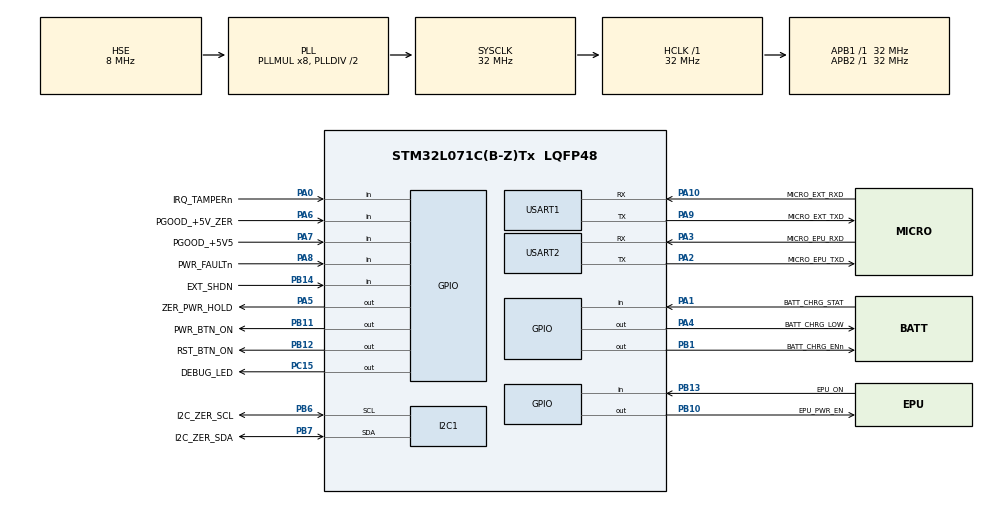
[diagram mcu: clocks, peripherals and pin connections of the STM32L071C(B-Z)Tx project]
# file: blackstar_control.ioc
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CRC.CRCLength=CRC_POLYLENGTH_16B
CRC.DefaultInitValueUse=DEFAULT_INIT_VALUE_DISABLE
CRC.DefaultPolynomialUse=DEFAULT_POLYNOMIAL_DISABLE
CRC.GeneratingPolynomial=X12+X5+X0
CRC.InitValue=0xFFFF
Dma.Request0=USART2_TX
Dma.Request1=USART2_RX
Dma.Request2=USART1_TX
Dma.Request3=USART1_RX
Dma.USART1_RX.3.Direction=DMA_PERIPH_TO_MEMORY
Dma.USART1_RX.3.Instance=DMA1_Channel3
Dma.USART1_RX.3.MemDataAlignment=DMA_MDATAALIGN_BYTE
Dma.USART1_RX.3.MemInc=DMA_MINC_ENABLE
Dma.USART1_RX.3.Mode=DMA_CIRCULAR
Dma.USART1_RX.3.PeriphDataAlignment=DMA_PDATAALIGN_BYTE
Dma.USART1_RX.3.PeriphInc=DMA_PINC_DISABLE
Dma.USART1_RX.3.Priority=DMA_PRIORITY_HIGH
Dma.USART1_TX.2.Direction=DMA_MEMORY_TO_PERIPH
Dma.USART1_TX.2.Instance=DMA1_Channel2
Dma.USART1_TX.2.MemDataAlignment=DMA_MDATAALIGN_BYTE
Dma.USART1_TX.2.MemInc=DMA_MINC_ENABLE
Dma.USART1_TX.2.Mode=DMA_NORMAL
Dma.USART1_TX.2.PeriphDataAlignment=DMA_PDATAALIGN_BYTE
Dma.USART1_TX.2.PeriphInc=DMA_PINC_DISABLE
Dma.USART1_TX.2.Priority=DMA_PRIORITY_LOW
Dma.USART2_RX.1.Direction=DMA_PERIPH_TO_MEMORY
Dma.USART2_RX.1.Instance=DMA1_Channel5
Dma.USART2_RX.1.MemDataAlignment=DMA_MDATAALIGN_BYTE
Dma.USART2_RX.1.MemInc=DMA_MINC_ENABLE
Dma.USART2_RX.1.Mode=DMA_CIRCULAR
Dma.USART2_RX.1.PeriphDataAlignment=DMA_PDATAALIGN_BYTE
Dma.USART2_RX.1.PeriphInc=DMA_PINC_DISABLE
Dma.USART2_RX.1.Priority=DMA_PRIORITY_HIGH
Dma.USART2_TX.0.Direction=DMA_MEMORY_TO_PERIPH
Dma.USART2_TX.0.Instance=DMA1_Channel4
Dma.USART2_TX.0.MemDataAlignment=DMA_MDATAALIGN_BYTE
Dma.USART2_TX.0.MemInc=DMA_MINC_ENABLE
Dma.USART2_TX.0.Mode=DMA_NORMAL
Dma.USART2_TX.0.PeriphDataAlignment=DMA_PDATAALIGN_BYTE
Dma.USART2_TX.0.PeriphInc=DMA_PINC_DISABLE
Dma.USART2_TX.0.Priority=DMA_PRIORITY_LOW
FREERTOS.BinarySemaphores01=uartTxSemaphore,Static,uartTxSemaphoreControlBlock
FREERTOS.Events01=uartEvents,Static,uartEventsControlBlock
FREERTOS.Queues01=epuTxQueue,2,TxQueueMsg_t,0,Static,epuTxQueueBuffer,epuTxQueueControlBlock;epuRxQueue,8,RxQueueMsg_t,0,Static,epuRxQueueBuffer,epuRxQueueControlBlock;extTxQueue,2,TxQueueMsg_t,0,Static,extTxQueueBuffer,extTxQueueControlBlock;extRxQueue,8,RxQueueMsg_t,0,Static,extRxQueueBuffer,extRxQueueControlBlock
FREERTOS.RecursiveMutexes01=crcMutex,Static,crcMutexControlBlock;i2cMutex,Static,i2cMutexControlBlock
FREERTOS.Tasks01=controllerTask,24,256,startControllerTask,Default,NULL,Static,controllerTaskBuffer,controllerTaskControlBlock;messageTask,24,1024,startMessageTask,Default,NULL,Static,messageTaskBuffer,messageTaskControlBlock;uartTask,32,256,startUartTask,Default,NULL,Static,uartTaskBuffer,uartTaskControlBlock
FREERTOS.configCHECK_FOR_STACK_OVERFLOW=2
FREERTOS.configRECORD_STACK_HIGH_ADDRESS=1
FREERTOS.configTOTAL_HEAP_SIZE=2048
FREERTOS.configUSE_NEWLIB_REENTRANT=1
I2C1.Speed=10
I2C1.Timing=0x6010C7FF
Mcu.Family=STM32L0
Mcu.Name=STM32L071C(B-Z)Tx
Mcu.Package=LQFP48
NVIC.DMA1_Channel2_3_IRQn=true\:3\:0\:false\:false\:false\:true\:false\:true\:true
NVIC.DMA1_Channel4_5_6_7_IRQn=true\:3\:0\:false\:false\:false\:true\:false\:true\:true
NVIC.I2C1_IRQn=true\:3\:0\:false\:false\:true\:true\:true\:true\:true
NVIC.TIM2_IRQn=true\:3\:0\:false\:false\:true\:false\:false\:true\:true
NVIC.TimeBase=TIM2_IRQn
NVIC.TimeBaseIP=TIM2
NVIC.USART1_IRQn=true\:3\:0\:false\:false\:false\:true\:true\:true\:true
NVIC.USART2_IRQn=true\:3\:0\:false\:false\:false\:true\:true\:true\:true
PA0.GPIO_Label=IRQ_TAMPERn
PA0.Signal=GPIO_Input
PA1.GPIO_Label=BATT_CHRG_STAT
PA1.Signal=GPIO_Input
PA10.GPIO_Label=MICRO_EXT_RXD
PA10.Mode=Asynchronous
PA10.Signal=USART1_RX
PA13.Mode=Serial_Wire
PA13.Signal=SYS_SWDIO
PA14.Mode=Serial_Wire
PA14.Signal=SYS_SWCLK
PA2.GPIO_Label=MICRO_EPU_TXD
PA2.Mode=Asynchronous
PA2.Signal=USART2_TX
PA3.GPIO_Label=MICRO_EPU_RXD
PA3.Mode=Asynchronous
PA3.Signal=USART2_RX
PA4.GPIO_Label=BATT_CHRG_LOW
PA4.GPIO_PuPd=GPIO_NOPULL
PA4.PinState=GPIO_PIN_RESET
PA4.Signal=GPIO_Output
PA5.GPIO_Label=ZER_PWR_HOLD
PA5.Signal=GPIO_Output
PA6.GPIO_Label=PGOOD_+5V_ZER
PA6.GPIO_PuPd=GPIO_PULLUP
PA6.Signal=GPIO_Input
PA7.GPIO_Label=PGOOD_+5V5
PA7.GPIO_PuPd=GPIO_PULLUP
PA7.Signal=GPIO_Input
PA8.GPIO_Label=PWR_FAULTn
PA8.GPIO_PuPd=GPIO_PULLUP
PA8.Signal=GPIO_Input
PA9.GPIO_Label=MICRO_EXT_TXD
PA9.Mode=Asynchronous
PA9.Signal=USART1_TX
PB1.GPIO_Label=BATT_CHRG_ENn
PB1.GPIO_PuPd=GPIO_NOPULL
PB1.Signal=GPIO_Output
PB10.GPIO_Label=EPU_PWR_EN
PB10.PinState=GPIO_PIN_RESET
PB10.Signal=GPIO_Output
PB11.GPIO_Label=PWR_BTN_ON
PB11.PinState=GPIO_PIN_RESET
PB11.Signal=GPIO_Output
PB12.GPIO_Label=RST_BTN_ON
PB12.PinState=GPIO_PIN_RESET
PB12.Signal=GPIO_Output
PB13.GPIO_Label=EPU_ON
PB13.GPIO_PuPd=GPIO_PULLDOWN
PB13.Signal=GPIO_Input
PB14.GPIO_Label=EXT_SHDN
PB14.Signal=GPIO_Input
PB6.GPIO_Label=I2C_ZER_SCL
PB6.GPIO_Pu=GPIO_PULLUP
PB6.Mode=I2C
PB6.Signal=I2C1_SCL
PB7.GPIO_Label=I2C_ZER_SDA
PB7.GPIO_Pu=GPIO_PULLUP
PB7.Mode=I2C
PB7.Signal=I2C1_SDA
PC15-OSC32_OUT.GPIO_Label=DEBUG_LED
PC15-OSC32_OUT.GPIO_PuPd=GPIO_NOPULL
PC15-OSC32_OUT.PinState=GPIO_PIN_RESET
PC15-OSC32_OUT.Signal=GPIO_Output
PH0-OSC_IN.Mode=HSE-External-Clock-Source
PH0-OSC_IN.Signal=RCC_OSC_IN
ProjectManager.HeapSize=0x200
ProjectManager.StackSize=0x400
ProjectManager.TargetToolchain=STM32CubeIDE
RCC.AHBFreq_Value=32000000
RCC.APB1Freq_Value=32000000
RCC.APB1TimFreq_Value=32000000
RCC.APB2Freq_Value=32000000
RCC.APB2TimFreq_Value=32000000
RCC.HCLKFreq_Value=32000000
RCC.HSE_VALUE=8000000
RCC.HSI16_VALUE=16000000
RCC.HSI_VALUE=16000000
RCC.LSE_VALUE=32768
RCC.MSI_VALUE=2097000
RCC.PLLMUL=RCC_PLLMUL_8
RCC.PLLSourceVirtual=RCC_PLLSOURCE_HSE
RCC.SYSCLKFreq_VALUE=32000000
RCC.SYSCLKSource=RCC_SYSCLKSOURCE_PLLCLK
RCC.VCOOutputFreq_Value=64000000
USART1.VirtualMode-Asynchronous=VM_ASYNC
USART2.VirtualMode-Asynchronous=VM_ASYNC
VP_CRC_VS_CRC.Mode=CRC_Activate
VP_FREERTOS_VS_CMSIS_V2.Mode=CMSIS_V2
VP_SYS_VS_tim2.Mode=TIM2
board=custom

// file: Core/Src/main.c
/* USER CODE BEGIN Header */
/**
  ******************************************************************************
  * @file           : main.c
  * @brief          : Main program body
  ******************************************************************************
  * @attention
  *
  * Copyright (c) 2023 STMicroelectronics.
  * All rights reserved.
  *
  * This software is licensed under terms that can be found in the LICENSE file
  * in the root directory of this software component.
  * If no LICENSE file comes with this software, it is provided AS-IS.
  *
  ******************************************************************************
  */
/* USER CODE END Header */
#include "main.h"
#include "cmsis_os.h"

/* USER CODE BEGIN Includes */
#include "Application/inc/ControllerTask.hpp"
#include "Application/inc/MessageTask.hpp"
#include "Application/inc/UartTask.hpp"
#include "Application/inc/Queues.hpp"
/* USER CODE END Includes */

typedef StaticTask_t osStaticThreadDef_t;
typedef StaticQueue_t osStaticMessageQDef_t;
typedef StaticSemaphore_t osStaticMutexDef_t;
typedef StaticSemaphore_t osStaticSemaphoreDef_t;
typedef StaticEventGroup_t osStaticEventGroupDef_t;

CRC_HandleTypeDef hcrc;

I2C_HandleTypeDef hi2c1;

/* Definitions for controllerTask */
osThreadId_t controllerTaskHandle;
uint32_t controllerTaskBuffer[ 256 ];
osStaticThreadDef_t controllerTaskControlBlock;
const osThreadAttr_t controllerTask_attributes = {
  .name = "controllerTask",
  .cb_mem = &controllerTaskControlBlock,
  .cb_size = sizeof(controllerTaskControlBlock),
  .stack_mem = &controllerTaskBuffer[0],
  .stack_size = sizeof(controllerTaskBuffer),
  .priority = (osPriority_t) osPriorityNormal,
};
/* Definitions for messageTask */
osThreadId_t messageTaskHandle;
uint32_t messageTaskBuffer[ 1024 ];
osStaticThreadDef_t messageTaskControlBlock;
const osThreadAttr_t messageTask_attributes = {
  .name = "messageTask",
  .cb_mem = &messageTaskControlBlock,
  .cb_size = sizeof(messageTaskControlBlock),
  .stack_mem = &messageTaskBuffer[0],
  .stack_size = sizeof(messageTaskBuffer),
  .priority = (osPriority_t) osPriorityNormal,
};
/* Definitions for uartTask */
osThreadId_t uartTaskHandle;
uint32_t uartTaskBuffer[ 256 ];
osStaticThreadDef_t uartTaskControlBlock;
const osThreadAttr_t uartTask_attributes = {
  .name = "uartTask",
  .cb_mem = &uartTaskControlBlock,
  .cb_size = sizeof(uartTaskControlBlock),
  .stack_mem = &uartTaskBuffer[0],
  .stack_size = sizeof(uartTaskBuffer),
  .priority = (osPriority_t) osPriorityAboveNormal,
};
/* Definitions for epuTxQueue */
osMessageQueueId_t epuTxQueueHandle;
uint8_t epuTxQueueBuffer[ 2 * sizeof( TxQueueMsg_t ) ];
osStaticMessageQDef_t epuTxQueueControlBlock;
const osMessageQueueAttr_t epuTxQueue_attributes = {
  .name = "epuTxQueue",
  .cb_mem = &epuTxQueueControlBlock,
  .cb_size = sizeof(epuTxQueueControlBlock),
  .mq_mem = &epuTxQueueBuffer,
  .mq_size = sizeof(epuTxQueueBuffer)
};
/* Definitions for epuRxQueue */
osMessageQueueId_t epuRxQueueHandle;
uint8_t epuRxQueueBuffer[ 8 * sizeof( RxQueueMsg_t ) ];
osStaticMessageQDef_t epuRxQueueControlBlock;
const osMessageQueueAttr_t epuRxQueue_attributes = {
  .name = "epuRxQueue",
  .cb_mem = &epuRxQueueControlBlock,
  .cb_size = sizeof(epuRxQueueControlBlock),
  .mq_mem = &epuRxQueueBuffer,
  .mq_size = sizeof(epuRxQueueBuffer)
};
/* Definitions for extTxQueue */
osMessageQueueId_t extTxQueueHandle;
uint8_t extTxQueueBuffer[ 2 * sizeof( TxQueueMsg_t ) ];
osStaticMessageQDef_t extTxQueueControlBlock;
const osMessageQueueAttr_t extTxQueue_attributes = {
  .name = "extTxQueue",
  .cb_mem = &extTxQueueControlBlock,
  .cb_size = sizeof(extTxQueueControlBlock),
  .mq_mem = &extTxQueueBuffer,
  .mq_size = sizeof(extTxQueueBuffer)
};
/* Definitions for extRxQueue */
osMessageQueueId_t extRxQueueHandle;
uint8_t extRxQueueBuffer[ 8 * sizeof( RxQueueMsg_t ) ];
osStaticMessageQDef_t extRxQueueControlBlock;
const osMessageQueueAttr_t extRxQueue_attributes = {
  .name = "extRxQueue",
  .cb_mem = &extRxQueueControlBlock,
  .cb_size = sizeof(extRxQueueControlBlock),
  .mq_mem = &extRxQueueBuffer,
  .mq_size = sizeof(extRxQueueBuffer)
};
/* Definitions for crcMutex */
osMutexId_t crcMutexHandle;
osStaticMutexDef_t crcMutexControlBlock;
const osMutexAttr_t crcMutex_attributes = {
  .name = "crcMutex",
  .attr_bits = osMutexRecursive,
  .cb_mem = &crcMutexControlBlock,
  .cb_size = sizeof(crcMutexControlBlock),
};
/* Definitions for i2cMutex */
osMutexId_t i2cMutexHandle;
osStaticMutexDef_t i2cMutexControlBlock;
const osMutexAttr_t i2cMutex_attributes = {
  .name = "i2cMutex",
  .attr_bits = osMutexRecursive,
  .cb_mem = &i2cMutexControlBlock,
  .cb_size = sizeof(i2cMutexControlBlock),
};
/* Definitions for uartTxSemaphore */
osSemaphoreId_t uartTxSemaphoreHandle;
osStaticSemaphoreDef_t uartTxSemaphoreControlBlock;
const osSemaphoreAttr_t uartTxSemaphore_attributes = {
  .name = "uartTxSemaphore",
  .cb_mem = &uartTxSemaphoreControlBlock,
  .cb_size = sizeof(uartTxSemaphoreControlBlock),
};
/* Definitions for uartEvents */
osEventFlagsId_t uartEventsHandle;
osStaticEventGroupDef_t uartEventsControlBlock;
const osEventFlagsAttr_t uartEvents_attributes = {
  .name = "uartEvents",
  .cb_mem = &uartEventsControlBlock,
  .cb_size = sizeof(uartEventsControlBlock),
};
/* USER CODE BEGIN PV */
uint32_t g_epuDMAHighWatermark;
uint32_t g_messageHighWatermark;
/* USER CODE END PV */

void SystemClock_Config(void);
static void MX_GPIO_Init(void);
static void MX_DMA_Init(void);
static void MX_I2C1_Init(void);
static void MX_USART1_UART_Init(void);
static void MX_USART2_UART_Init(void);
static void MX_CRC_Init(void);
void startControllerTask(void *argument);
void startMessageTask(void *argument);
void startUartTask(void *argument);

/* USER CODE BEGIN 0 */
__weak void debug_printf(const char *fmt, ...)
{
    // do nothing
}
/* USER CODE END 0 */

int main(void)
{

  /* MCU Configuration--------------------------------------------------------*/

  /* Reset of all peripherals, Initializes the Flash interface and the Systick. */
  HAL_Init();

  /* Configure the system clock */
  SystemClock_Config();

  /* Initialize all configured peripherals */
  MX_GPIO_Init();
  MX_DMA_Init();
  MX_I2C1_Init();
  MX_USART1_UART_Init();
  MX_USART2_UART_Init();
  MX_CRC_Init();

  /* Init scheduler */
  osKernelInitialize();

  /* Create the recursive mutex(es) */
  /* creation of crcMutex */
  crcMutexHandle = osMutexNew(&crcMutex_attributes);

  /* creation of i2cMutex */
  i2cMutexHandle = osMutexNew(&i2cMutex_attributes);

  /* Create the semaphores(s) */
  /* creation of uartTxSemaphore */
  uartTxSemaphoreHandle = osSemaphoreNew(1, 1, &uartTxSemaphore_attributes);

  /* Create the queue(s) */
  /* creation of epuTxQueue */
  epuTxQueueHandle = osMessageQueueNew (2, sizeof(TxQueueMsg_t), &epuTxQueue_attributes);

  /* creation of epuRxQueue */
  epuRxQueueHandle = osMessageQueueNew (8, sizeof(RxQueueMsg_t), &epuRxQueue_attributes);

  /* creation of extTxQueue */
  extTxQueueHandle = osMessageQueueNew (2, sizeof(TxQueueMsg_t), &extTxQueue_attributes);

  /* creation of extRxQueue */
  extRxQueueHandle = osMessageQueueNew (8, sizeof(RxQueueMsg_t), &extRxQueue_attributes);

  /* Create the thread(s) */
  /* creation of controllerTask */
  controllerTaskHandle = osThreadNew(startControllerTask, NULL, &controllerTask_attributes);

  /* creation of messageTask */
  messageTaskHandle = osThreadNew(startMessageTask, NULL, &messageTask_attributes);

  /* creation of uartTask */
  uartTaskHandle = osThreadNew(startUartTask, NULL, &uartTask_attributes);

  /* Create the event(s) */
  /* creation of uartEvents */
  uartEventsHandle = osEventFlagsNew(&uartEvents_attributes);

  /* Start scheduler */
  osKernelStart();
  /* We should never get here as control is now taken by the scheduler */
  /* Infinite loop */
  while (1)
  {

  }
}

void SystemClock_Config(void)
{
  RCC_OscInitTypeDef RCC_OscInitStruct = {0};
  RCC_ClkInitTypeDef RCC_ClkInitStruct = {0};
  RCC_PeriphCLKInitTypeDef PeriphClkInit = {0};

  /** Configure the main internal regulator output voltage
  */
  __HAL_PWR_VOLTAGESCALING_CONFIG(PWR_REGULATOR_VOLTAGE_SCALE1);

  /** Initializes the RCC Oscillators according to the specified parameters
  * in the RCC_OscInitTypeDef structure.
  */
  RCC_OscInitStruct.OscillatorType = RCC_OSCILLATORTYPE_HSE;
  RCC_OscInitStruct.HSEState = RCC_HSE_BYPASS;
  RCC_OscInitStruct.PLL.PLLState = RCC_PLL_ON;
  RCC_OscInitStruct.PLL.PLLSource = RCC_PLLSOURCE_HSE;
  RCC_OscInitStruct.PLL.PLLMUL = RCC_PLLMUL_8;
  RCC_OscInitStruct.PLL.PLLDIV = RCC_PLLDIV_2;
  if (HAL_RCC_OscConfig(&RCC_OscInitStruct) != HAL_OK)
  {
    Error_Handler();
  }

  /** Initializes the CPU, AHB and APB buses clocks
  */
  RCC_ClkInitStruct.ClockType = RCC_CLOCKTYPE_HCLK|RCC_CLOCKTYPE_SYSCLK
                              |RCC_CLOCKTYPE_PCLK1|RCC_CLOCKTYPE_PCLK2;
  RCC_ClkInitStruct.SYSCLKSource = RCC_SYSCLKSOURCE_PLLCLK;
  RCC_ClkInitStruct.AHBCLKDivider = RCC_SYSCLK_DIV1;
  RCC_ClkInitStruct.APB1CLKDivider = RCC_HCLK_DIV1;
  RCC_ClkInitStruct.APB2CLKDivider = RCC_HCLK_DIV1;

  if (HAL_RCC_ClockConfig(&RCC_ClkInitStruct, FLASH_LATENCY_1) != HAL_OK)
  {
    Error_Handler();
  }
  PeriphClkInit.PeriphClockSelection = RCC_PERIPHCLK_USART1|RCC_PERIPHCLK_USART2
                              |RCC_PERIPHCLK_I2C1;
  PeriphClkInit.Usart1ClockSelection = RCC_USART1CLKSOURCE_PCLK2;
  PeriphClkInit.Usart2ClockSelection = RCC_USART2CLKSOURCE_PCLK1;
  PeriphClkInit.I2c1ClockSelection = RCC_I2C1CLKSOURCE_PCLK1;
  if (HAL_RCCEx_PeriphCLKConfig(&PeriphClkInit) != HAL_OK)
  {
    Error_Handler();
  }
}

static void MX_CRC_Init(void)
{

  hcrc.Instance = CRC;
  hcrc.Init.DefaultPolynomialUse = DEFAULT_POLYNOMIAL_DISABLE;
  hcrc.Init.DefaultInitValueUse = DEFAULT_INIT_VALUE_DISABLE;
  hcrc.Init.GeneratingPolynomial = 4129;
  hcrc.Init.CRCLength = CRC_POLYLENGTH_16B;
  hcrc.Init.InitValue = 0xFFFF;
  hcrc.Init.InputDataInversionMode = CRC_INPUTDATA_INVERSION_NONE;
  hcrc.Init.OutputDataInversionMode = CRC_OUTPUTDATA_INVERSION_DISABLE;
  hcrc.InputDataFormat = CRC_INPUTDATA_FORMAT_BYTES;
  if (HAL_CRC_Init(&hcrc) != HAL_OK)
  {
    Error_Handler();
  }

}

static void MX_I2C1_Init(void)
{

  hi2c1.Instance = I2C1;
  hi2c1.Init.Timing = 0x6010C7FF;
  hi2c1.Init.OwnAddress1 = 0;
  hi2c1.Init.AddressingMode = I2C_ADDRESSINGMODE_7BIT;
  hi2c1.Init.DualAddressMode = I2C_DUALADDRESS_DISABLE;
  hi2c1.Init.OwnAddress2 = 0;
  hi2c1.Init.OwnAddress2Masks = I2C_OA2_NOMASK;
  hi2c1.Init.GeneralCallMode = I2C_GENERALCALL_DISABLE;
  hi2c1.Init.NoStretchMode = I2C_NOSTRETCH_DISABLE;
  if (HAL_I2C_Init(&hi2c1) != HAL_OK)
  {
    Error_Handler();
  }

  /** Configure Analogue filter
  */
  if (HAL_I2CEx_ConfigAnalogFilter(&hi2c1, I2C_ANALOGFILTER_ENABLE) != HAL_OK)
  {
    Error_Handler();
  }

  /** Configure Digital filter
  */
  if (HAL_I2CEx_ConfigDigitalFilter(&hi2c1, 0) != HAL_OK)
  {
    Error_Handler();
  }

}

static void MX_USART1_UART_Init(void)
{

  LL_USART_InitTypeDef USART_InitStruct = {0};

  LL_GPIO_InitTypeDef GPIO_InitStruct = {0};

  /* Peripheral clock enable */
  LL_APB2_GRP1_EnableClock(LL_APB2_GRP1_PERIPH_USART1);

  LL_IOP_GRP1_EnableClock(LL_IOP_GRP1_PERIPH_GPIOA);
  /**USART1 GPIO Configuration
  PA9   ------> USART1_TX
  PA10   ------> USART1_RX
  */
  GPIO_InitStruct.Pin = LL_GPIO_PIN_9;
  GPIO_InitStruct.Mode = LL_GPIO_MODE_ALTERNATE;
  GPIO_InitStruct.Speed = LL_GPIO_SPEED_FREQ_VERY_HIGH;
  GPIO_InitStruct.OutputType = LL_GPIO_OUTPUT_PUSHPULL;
  GPIO_InitStruct.Pull = LL_GPIO_PULL_NO;
  GPIO_InitStruct.Alternate = LL_GPIO_AF_4;
  LL_GPIO_Init(GPIOA, &GPIO_InitStruct);

  GPIO_InitStruct.Pin = LL_GPIO_PIN_10;
  GPIO_InitStruct.Mode = LL_GPIO_MODE_ALTERNATE;
  GPIO_InitStruct.Speed = LL_GPIO_SPEED_FREQ_VERY_HIGH;
  GPIO_InitStruct.OutputType = LL_GPIO_OUTPUT_PUSHPULL;
  GPIO_InitStruct.Pull = LL_GPIO_PULL_NO;
  GPIO_InitStruct.Alternate = LL_GPIO_AF_4;
  LL_GPIO_Init(GPIOA, &GPIO_InitStruct);

  /* USART1 DMA Init */

  /* USART1_TX Init */
  LL_DMA_SetPeriphRequest(DMA1, LL_DMA_CHANNEL_2, LL_DMA_REQUEST_3);

  LL_DMA_SetDataTransferDirection(DMA1, LL_DMA_CHANNEL_2, LL_DMA_DIRECTION_MEMORY_TO_PERIPH);

  LL_DMA_SetChannelPriorityLevel(DMA1, LL_DMA_CHANNEL_2, LL_DMA_PRIORITY_LOW);

  LL_DMA_SetMode(DMA1, LL_DMA_CHANNEL_2, LL_DMA_MODE_NORMAL);

  LL_DMA_SetPeriphIncMode(DMA1, LL_DMA_CHANNEL_2, LL_DMA_PERIPH_NOINCREMENT);

  LL_DMA_SetMemoryIncMode(DMA1, LL_DMA_CHANNEL_2, LL_DMA_MEMORY_INCREMENT);

  LL_DMA_SetPeriphSize(DMA1, LL_DMA_CHANNEL_2, LL_DMA_PDATAALIGN_BYTE);

  LL_DMA_SetMemorySize(DMA1, LL_DMA_CHANNEL_2, LL_DMA_MDATAALIGN_BYTE);

  /* USART1_RX Init */
  LL_DMA_SetPeriphRequest(DMA1, LL_DMA_CHANNEL_3, LL_DMA_REQUEST_3);

  LL_DMA_SetDataTransferDirection(DMA1, LL_DMA_CHANNEL_3, LL_DMA_DIRECTION_PERIPH_TO_MEMORY);

  LL_DMA_SetChannelPriorityLevel(DMA1, LL_DMA_CHANNEL_3, LL_DMA_PRIORITY_HIGH);

  LL_DMA_SetMode(DMA1, LL_DMA_CHANNEL_3, LL_DMA_MODE_CIRCULAR);

  LL_DMA_SetPeriphIncMode(DMA1, LL_DMA_CHANNEL_3, LL_DMA_PERIPH_NOINCREMENT);

  LL_DMA_SetMemoryIncMode(DMA1, LL_DMA_CHANNEL_3, LL_DMA_MEMORY_INCREMENT);

  LL_DMA_SetPeriphSize(DMA1, LL_DMA_CHANNEL_3, LL_DMA_PDATAALIGN_BYTE);

  LL_DMA_SetMemorySize(DMA1, LL_DMA_CHANNEL_3, LL_DMA_MDATAALIGN_BYTE);

  /* USART1 interrupt Init */
  NVIC_SetPriority(USART1_IRQn, 3);
  NVIC_EnableIRQ(USART1_IRQn);

  USART_InitStruct.BaudRate = 115200;
  USART_InitStruct.DataWidth = LL_USART_DATAWIDTH_8B;
  USART_InitStruct.StopBits = LL_USART_STOPBITS_1;
  USART_InitStruct.Parity = LL_USART_PARITY_NONE;
  USART_InitStruct.TransferDirection = LL_USART_DIRECTION_TX_RX;
  USART_InitStruct.HardwareFlowControl = LL_USART_HWCONTROL_NONE;
  USART_InitStruct.OverSampling = LL_USART_OVERSAMPLING_16;
  LL_USART_Init(USART1, &USART_InitStruct);
  LL_USART_ConfigAsyncMode(USART1);
  LL_USART_Enable(USART1);

}

static void MX_USART2_UART_Init(void)
{

  LL_USART_InitTypeDef USART_InitStruct = {0};

  LL_GPIO_InitTypeDef GPIO_InitStruct = {0};

  /* Peripheral clock enable */
  LL_APB1_GRP1_EnableClock(LL_APB1_GRP1_PERIPH_USART2);

  LL_IOP_GRP1_EnableClock(LL_IOP_GRP1_PERIPH_GPIOA);
  /**USART2 GPIO Configuration
  PA2   ------> USART2_TX
  PA3   ------> USART2_RX
  */
  GPIO_InitStruct.Pin = LL_GPIO_PIN_2;
  GPIO_InitStruct.Mode = LL_GPIO_MODE_ALTERNATE;
  GPIO_InitStruct.Speed = LL_GPIO_SPEED_FREQ_VERY_HIGH;
  GPIO_InitStruct.OutputType = LL_GPIO_OUTPUT_PUSHPULL;
  GPIO_InitStruct.Pull = LL_GPIO_PULL_NO;
  GPIO_InitStruct.Alternate = LL_GPIO_AF_4;
  LL_GPIO_Init(GPIOA, &GPIO_InitStruct);

  GPIO_InitStruct.Pin = LL_GPIO_PIN_3;
  GPIO_InitStruct.Mode = LL_GPIO_MODE_ALTERNATE;
  GPIO_InitStruct.Speed = LL_GPIO_SPEED_FREQ_VERY_HIGH;
  GPIO_InitStruct.OutputType = LL_GPIO_OUTPUT_PUSHPULL;
  GPIO_InitStruct.Pull = LL_GPIO_PULL_NO;
  GPIO_InitStruct.Alternate = LL_GPIO_AF_4;
  LL_GPIO_Init(GPIOA, &GPIO_InitStruct);

  /* USART2 DMA Init */

  /* USART2_TX Init */
  LL_DMA_SetPeriphRequest(DMA1, LL_DMA_CHANNEL_4, LL_DMA_REQUEST_4);

  LL_DMA_SetDataTransferDirection(DMA1, LL_DMA_CHANNEL_4, LL_DMA_DIRECTION_MEMORY_TO_PERIPH);

  LL_DMA_SetChannelPriorityLevel(DMA1, LL_DMA_CHANNEL_4, LL_DMA_PRIORITY_LOW);

  LL_DMA_SetMode(DMA1, LL_DMA_CHANNEL_4, LL_DMA_MODE_NORMAL);

  LL_DMA_SetPeriphIncMode(DMA1, LL_DMA_CHANNEL_4, LL_DMA_PERIPH_NOINCREMENT);

  LL_DMA_SetMemoryIncMode(DMA1, LL_DMA_CHANNEL_4, LL_DMA_MEMORY_INCREMENT);

  LL_DMA_SetPeriphSize(DMA1, LL_DMA_CHANNEL_4, LL_DMA_PDATAALIGN_BYTE);

  LL_DMA_SetMemorySize(DMA1, LL_DMA_CHANNEL_4, LL_DMA_MDATAALIGN_BYTE);

  /* USART2_RX Init */
  LL_DMA_SetPeriphRequest(DMA1, LL_DMA_CHANNEL_5, LL_DMA_REQUEST_4);

  LL_DMA_SetDataTransferDirection(DMA1, LL_DMA_CHANNEL_5, LL_DMA_DIRECTION_PERIPH_TO_MEMORY);

  LL_DMA_SetChannelPriorityLevel(DMA1, LL_DMA_CHANNEL_5, LL_DMA_PRIORITY_HIGH);

  LL_DMA_SetMode(DMA1, LL_DMA_CHANNEL_5, LL_DMA_MODE_CIRCULAR);

  LL_DMA_SetPeriphIncMode(DMA1, LL_DMA_CHANNEL_5, LL_DMA_PERIPH_NOINCREMENT);

  LL_DMA_SetMemoryIncMode(DMA1, LL_DMA_CHANNEL_5, LL_DMA_MEMORY_INCREMENT);

  LL_DMA_SetPeriphSize(DMA1, LL_DMA_CHANNEL_5, LL_DMA_PDATAALIGN_BYTE);

  LL_DMA_SetMemorySize(DMA1, LL_DMA_CHANNEL_5, LL_DMA_MDATAALIGN_BYTE);

  /* USART2 interrupt Init */
  NVIC_SetPriority(USART2_IRQn, 3);
  NVIC_EnableIRQ(USART2_IRQn);

  USART_InitStruct.BaudRate = 115200;
  USART_InitStruct.DataWidth = LL_USART_DATAWIDTH_8B;
  USART_InitStruct.StopBits = LL_USART_STOPBITS_1;
  USART_InitStruct.Parity = LL_USART_PARITY_NONE;
  USART_InitStruct.TransferDirection = LL_USART_DIRECTION_TX_RX;
  USART_InitStruct.HardwareFlowControl = LL_USART_HWCONTROL_NONE;
  USART_InitStruct.OverSampling = LL_USART_OVERSAMPLING_16;
  LL_USART_Init(USART2, &USART_InitStruct);
  LL_USART_ConfigAsyncMode(USART2);
  LL_USART_Enable(USART2);

}

static void MX_DMA_Init(void)
{

  /* DMA controller clock enable */
  __HAL_RCC_DMA1_CLK_ENABLE();

  /* DMA interrupt init */
  /* DMA1_Channel2_3_IRQn interrupt configuration */
  NVIC_SetPriority(DMA1_Channel2_3_IRQn, 3);
  NVIC_EnableIRQ(DMA1_Channel2_3_IRQn);
  /* DMA1_Channel4_5_6_7_IRQn interrupt configuration */
  NVIC_SetPriority(DMA1_Channel4_5_6_7_IRQn, 3);
  NVIC_EnableIRQ(DMA1_Channel4_5_6_7_IRQn);

}

static void MX_GPIO_Init(void)
{
  GPIO_InitTypeDef GPIO_InitStruct = {0};

  /* GPIO Ports Clock Enable */
  __HAL_RCC_GPIOC_CLK_ENABLE();
  __HAL_RCC_GPIOH_CLK_ENABLE();
  __HAL_RCC_GPIOA_CLK_ENABLE();
  __HAL_RCC_GPIOB_CLK_ENABLE();

  /*Configure GPIO pin Output Level */
  HAL_GPIO_WritePin(DEBUG_LED_GPIO_Port, DEBUG_LED_Pin, GPIO_PIN_RESET);

  /*Configure GPIO pin Output Level */
  HAL_GPIO_WritePin(GPIOA, BATT_CHRG_LOW_Pin|ZER_PWR_HOLD_Pin, GPIO_PIN_RESET);

  /*Configure GPIO pin Output Level */
  HAL_GPIO_WritePin(GPIOB, BATT_CHRG_ENn_Pin|EPU_PWR_EN_Pin|PWR_BTN_ON_Pin|RST_BTN_ON_Pin, GPIO_PIN_RESET);

  /*Configure GPIO pin : DEBUG_LED_Pin */
  GPIO_InitStruct.Pin = DEBUG_LED_Pin;
  GPIO_InitStruct.Mode = GPIO_MODE_OUTPUT_PP;
  GPIO_InitStruct.Pull = GPIO_NOPULL;
  GPIO_InitStruct.Speed = GPIO_SPEED_FREQ_LOW;
  HAL_GPIO_Init(DEBUG_LED_GPIO_Port, &GPIO_InitStruct);

  /*Configure GPIO pins : IRQ_TAMPERn_Pin BATT_CHRG_STAT_Pin */
  GPIO_InitStruct.Pin = IRQ_TAMPERn_Pin|BATT_CHRG_STAT_Pin;
  GPIO_InitStruct.Mode = GPIO_MODE_INPUT;
  GPIO_InitStruct.Pull = GPIO_NOPULL;
  HAL_GPIO_Init(GPIOA, &GPIO_InitStruct);

  /*Configure GPIO pins : BATT_CHRG_LOW_Pin ZER_PWR_HOLD_Pin */
  GPIO_InitStruct.Pin = BATT_CHRG_LOW_Pin|ZER_PWR_HOLD_Pin;
  GPIO_InitStruct.Mode = GPIO_MODE_OUTPUT_PP;
  GPIO_InitStruct.Pull = GPIO_NOPULL;
  GPIO_InitStruct.Speed = GPIO_SPEED_FREQ_LOW;
  HAL_GPIO_Init(GPIOA, &GPIO_InitStruct);

  /*Configure GPIO pins : PGOOD__5V_ZER_Pin PGOOD__5V5_Pin PWR_FAULTn_Pin */
  GPIO_InitStruct.Pin = PGOOD__5V_ZER_Pin|PGOOD__5V5_Pin|PWR_FAULTn_Pin;
  GPIO_InitStruct.Mode = GPIO_MODE_INPUT;
  GPIO_InitStruct.Pull = GPIO_PULLUP;
  HAL_GPIO_Init(GPIOA, &GPIO_InitStruct);

  /*Configure GPIO pins : BATT_CHRG_ENn_Pin EPU_PWR_EN_Pin PWR_BTN_ON_Pin RST_BTN_ON_Pin */
  GPIO_InitStruct.Pin = BATT_CHRG_ENn_Pin|EPU_PWR_EN_Pin|PWR_BTN_ON_Pin|RST_BTN_ON_Pin;
  GPIO_InitStruct.Mode = GPIO_MODE_OUTPUT_PP;
  GPIO_InitStruct.Pull = GPIO_NOPULL;
  GPIO_InitStruct.Speed = GPIO_SPEED_FREQ_LOW;
  HAL_GPIO_Init(GPIOB, &GPIO_InitStruct);

  /*Configure GPIO pin : EPU_ON_Pin */
  GPIO_InitStruct.Pin = EPU_ON_Pin;
  GPIO_InitStruct.Mode = GPIO_MODE_INPUT;
  GPIO_InitStruct.Pull = GPIO_PULLDOWN;
  HAL_GPIO_Init(EPU_ON_GPIO_Port, &GPIO_InitStruct);

  /*Configure GPIO pin : EXT_SHDN_Pin */
  GPIO_InitStruct.Pin = EXT_SHDN_Pin;
  GPIO_InitStruct.Mode = GPIO_MODE_INPUT;
  GPIO_InitStruct.Pull = GPIO_NOPULL;
  HAL_GPIO_Init(EXT_SHDN_GPIO_Port, &GPIO_InitStruct);

}

void startControllerTask(void *argument)
{
  /* USER CODE BEGIN 5 */
  controllerTaskRun();
  /* USER CODE END 5 */
}

void startMessageTask(void *argument)
{
  /* USER CODE BEGIN startMessageTask */
  messageTaskRun();
  /* USER CODE END startMessageTask */
}

void startUartTask(void *argument)
{
  /* USER CODE BEGIN startUartTask */
  uartTaskRun();
  /* USER CODE END startUartTask */
}

void HAL_TIM_PeriodElapsedCallback(TIM_HandleTypeDef *htim)
{
  if (htim->Instance == TIM2) {
    HAL_IncTick();
  }
}

void Error_Handler(void)
{
  __disable_irq();
  while (1)
  {
  }
}
